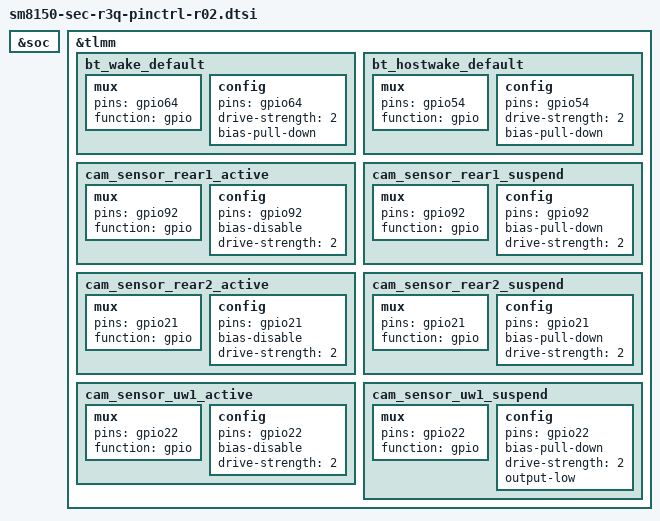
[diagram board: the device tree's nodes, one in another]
/* Copyright (c) 2016-2017, The Linux Foundation. All rights reserved.
 *
 * This program is free software; you can redistribute it and/or modify
 * it under the terms of the GNU General Public License version 2 and
 * only version 2 as published by the Free Software Foundation.
 *
 * This program is distributed in the hope that it will be useful,
 * but WITHOUT ANY WARRANTY; without even the implied warranty of
 * MERCHANTABILITY or FITNESS FOR A PARTICULAR PURPOSE.  See the
 * GNU General Public License for more details.
 */

#include "sm8150-sec-r3q-pinctrl-common.dtsi"
#include "../../../../../drivers/motor/tuning/beyondxq_motor_tuning.dtsi"

&soc {
	/* tlmm: pinctrl@03400000 { }; */
};
&tlmm {
	bt_wake_default: bt_wake_default {
		mux {
			pins = "gpio64";
			function = "gpio";
		};
		config {
			pins = "gpio64";
			drive-strength = <2>;
			bias-pull-down;
		};
	};
	bt_hostwake_default: bt_hostwake_default {
		mux {
			pins = "gpio54";
			function = "gpio";
		};
		config {
			pins = "gpio54";
			drive-strength = <2>;
			bias-pull-down;
		};
	};
        cam_sensor_rear1_active: cam_sensor_rear1_active {
                /* RESET REAR1 */
                mux {
                        pins = "gpio92";
                        function = "gpio";
                };
                config {
                        pins = "gpio92";
                        bias-disable; /* No PULL */
                        drive-strength = <2>; /* 2 MA */
                };
        };

        cam_sensor_rear1_suspend: cam_sensor_rear1_suspend {
                /* REAR1 RESET */
                mux {
                        pins = "gpio92";
                        function = "gpio";
                };
                config {
                        pins = "gpio92";
                        bias-pull-down; /* PULL DOWN */
                        drive-strength = <2>; /* 2 MA */
                };
        };
        cam_sensor_rear2_active: cam_sensor_rear2_active {
                /* RESET REAR2 */
                mux {
                        pins = "gpio21";
                        function = "gpio";
                };
                config {
                        pins = "gpio21";
                        bias-disable; /* No PULL */
                        drive-strength = <2>; /* 2 MA */
                };
        };

        cam_sensor_rear2_suspend: cam_sensor_rear2_suspend {
                /* REAR2 RESET */
                mux {
                    pins = "gpio21";
                    function = "gpio";
                };
                config {
                    pins = "gpio21";
                    bias-pull-down; /* PULL DOWN */
                    drive-strength = <2>; /* 2 MA */
                };
        };

        cam_sensor_uw1_active: cam_sensor_uw1_active {
		/* RESET ULTRAWIDE */
		mux {
			pins = "gpio22";
			function = "gpio";
		};
		config {
			pins = "gpio22";
			bias-disable; /* No PULL */
			drive-strength = <2>; /* 2 MA */
		};
	};

	cam_sensor_uw1_suspend: cam_sensor_uw1_suspend {
		/* RESET ULTRAWIDE */
		mux {
			pins = "gpio22";
			function = "gpio";
		};
		config {
			pins = "gpio22";
			bias-pull-down; /* PULL DOWN */
			drive-strength = <2>; /* 2 MA */
			output-low;
		};
	};
};
